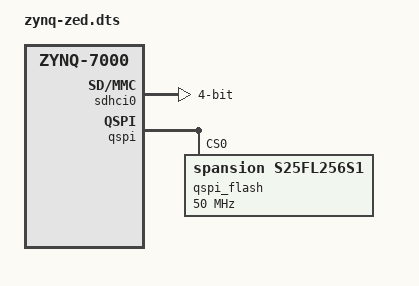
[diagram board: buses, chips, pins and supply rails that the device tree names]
#include <arm/xilinx/zynq-zed.dts>
#include "zynq-7000.dtsi"

/ {
	barebox,disable-deep-probe;

	chosen {
		stdout-path = &uart1;

		environment-sd {
			compatible = "barebox,environment";
			device-path = &sdhci0, "partname:0";
			file-path = "barebox.env";
		};
	};
};

&sdhci0 {
	bus-width = <4>;
};

&qspi {
	status = "okay";
	num-cs = <1>;

	qspi_flash: flash@0 {
		compatible = "spansion,s25fl256s1", "jedec,spi-nor";
		reg = <0>;
		spi-tx-bus-width = <1>;
		spi-rx-bus-width = <4>;
		spi-max-frequency = <50000000>;
		m25p,fast-read;

		#address-cells = <1>;
		#size-cells = <1>;
	};
};
